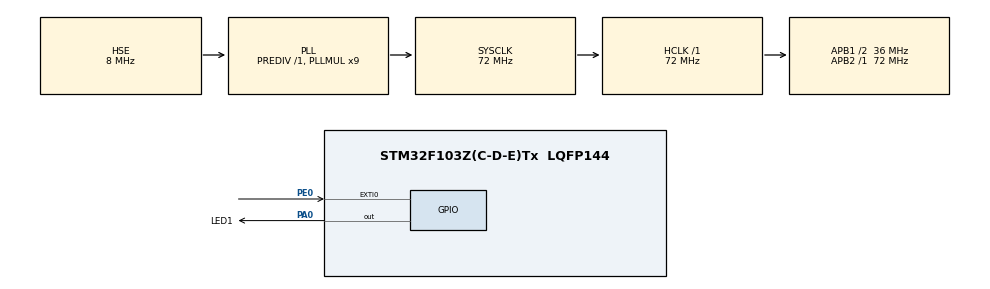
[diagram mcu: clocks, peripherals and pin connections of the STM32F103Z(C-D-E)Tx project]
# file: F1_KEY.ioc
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Mcu.Family=STM32F1
Mcu.Name=STM32F103Z(C-D-E)Tx
Mcu.Package=LQFP144
NVIC.EXTI0_IRQn=true\:0\:0\:false\:false\:true\:true\:true
NVIC.PriorityGroup=NVIC_PRIORITYGROUP_4
OSC_IN.Mode=HSE-External-Oscillator
OSC_IN.Signal=RCC_OSC_IN
OSC_OUT.Mode=HSE-External-Oscillator
OSC_OUT.Signal=RCC_OSC_OUT
PA0-WKUP.GPIO_Label=LED1
PA0-WKUP.PinState=GPIO_PIN_SET
PA0-WKUP.Signal=GPIO_Output
PA13.Mode=Serial_Wire
PA13.Signal=SYS_JTMS-SWDIO
PA14.Mode=Serial_Wire
PA14.Signal=SYS_JTCK-SWCLK
PE0.GPIO_ModeDefaultEXTI=GPIO_MODE_IT_FALLING
PE0.Signal=GPXTI0
ProjectManager.HeapSize=0x200
ProjectManager.StackSize=0x400
ProjectManager.TargetToolchain=MDK-ARM V5
RCC.AHBFreq_Value=72000000
RCC.APB1CLKDivider=RCC_HCLK_DIV2
RCC.APB1Freq_Value=36000000
RCC.APB1TimFreq_Value=72000000
RCC.APB2Freq_Value=72000000
RCC.APB2TimFreq_Value=72000000
RCC.HCLKFreq_Value=72000000
RCC.PLLMUL=RCC_PLL_MUL9
RCC.PLLSourceVirtual=RCC_PLLSOURCE_HSE
RCC.SYSCLKFreq_VALUE=72000000
RCC.SYSCLKSource=RCC_SYSCLKSOURCE_PLLCLK
RCC.USBFreq_Value=72000000
board=custom

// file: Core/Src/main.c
/* USER CODE BEGIN Header */
/**
  ******************************************************************************
  * @file           : main.c
  * @brief          : Main program body
  ******************************************************************************
  * @attention
  *
  * <h2><center>&copy; Copyright (c) 2019 STMicroelectronics.
  * All rights reserved.</center></h2>
  *
  * This software component is licensed by ST under BSD 3-Clause license,
  * the "License"; You may not use this file except in compliance with the
  * License. You may obtain a copy of the License at:
  *                        opensource.org/licenses/BSD-3-Clause
  *
  ******************************************************************************
  */
/* USER CODE END Header */

#include "main.h"
#include "gpio.h"

/* USER CODE BEGIN Includes */
#include "key.h"
#include "led.h"

/* USER CODE END Includes */

/* USER CODE BEGIN PV */
static volatile uint8_t flag = 0;

/* USER CODE END PV */

void SystemClock_Config(void);

int main(void)
{

  /* MCU Configuration--------------------------------------------------------*/

  /* Reset of all peripherals, Initializes the Flash interface and the Systick. */
  HAL_Init();

  /* Configure the system clock */
  SystemClock_Config();

  /* Initialize all configured peripherals */
  MX_GPIO_Init();
  /* USER CODE BEGIN 2 */
  uint32_t old_tick = HAL_GetTick();
  uint8_t status = 0;

  /* USER CODE END 2 */

  /* Infinite loop */
  /* USER CODE BEGIN WHILE */
  while (1)
  {
#if KEY_MODE == 0
	  if(KeyReadStatus() == KEY_PRESS)
	  {
		  HAL_Delay(10);
		  if(KeyReadStatus() == KEY_PRESS)
		  {
			  LED_Control(LED_ON);
			  while(KeyReadStatus() == KEY_PRESS);
			  LED_Control(LED_OFF);
		  }
	  }

#elif KEY_MODE == 1

	  uint32_t new_tick;
	  new_tick = HAL_GetTick();

	  if(new_tick > (old_tick + 10))
	  {
		  old_tick = new_tick;
          if(KeyReadStatus() == KEY_PRESS)
          {
                if(status == 0)
                    status = 1;
                else if(status == 1)
                {
                    status = 2;
                    LED_Control(LED_ON);
                }
          }
		  else
		  {
				if(status == 2)
				{
					status = 0;
					LED_Control(LED_OFF);
				}
		  }

	  }

#elif KEY_MODE == 2

	if(flag)
	{
		flag = 0;
		LED_Control(LED_ON);
	}

#elif KEY_MODE == 3

	HAL_PWR_EnterSTOPMode(PWR_LOWPOWERREGULATOR_ON, PWR_STOPENTRY_WFI);		//开启低功耗stop模式
	SystemClock_Config();		//重新配置时钟
	LED_Control(LED_ON);

#endif
    /* USER CODE END WHILE */

  }
}

void SystemClock_Config(void)
{
  RCC_OscInitTypeDef RCC_OscInitStruct = {0};
  RCC_ClkInitTypeDef RCC_ClkInitStruct = {0};

  /** Initializes the CPU, AHB and APB busses clocks
  */
  RCC_OscInitStruct.OscillatorType = RCC_OSCILLATORTYPE_HSE;
  RCC_OscInitStruct.HSEState = RCC_HSE_ON;
  RCC_OscInitStruct.HSEPredivValue = RCC_HSE_PREDIV_DIV1;
  RCC_OscInitStruct.HSIState = RCC_HSI_ON;
  RCC_OscInitStruct.PLL.PLLState = RCC_PLL_ON;
  RCC_OscInitStruct.PLL.PLLSource = RCC_PLLSOURCE_HSE;
  RCC_OscInitStruct.PLL.PLLMUL = RCC_PLL_MUL9;
  if (HAL_RCC_OscConfig(&RCC_OscInitStruct) != HAL_OK)
  {
    Error_Handler();
  }
  /** Initializes the CPU, AHB and APB busses clocks
  */
  RCC_ClkInitStruct.ClockType = RCC_CLOCKTYPE_HCLK|RCC_CLOCKTYPE_SYSCLK
                              |RCC_CLOCKTYPE_PCLK1|RCC_CLOCKTYPE_PCLK2;
  RCC_ClkInitStruct.SYSCLKSource = RCC_SYSCLKSOURCE_PLLCLK;
  RCC_ClkInitStruct.AHBCLKDivider = RCC_SYSCLK_DIV1;
  RCC_ClkInitStruct.APB1CLKDivider = RCC_HCLK_DIV2;
  RCC_ClkInitStruct.APB2CLKDivider = RCC_HCLK_DIV1;

  if (HAL_RCC_ClockConfig(&RCC_ClkInitStruct, FLASH_LATENCY_2) != HAL_OK)
  {
    Error_Handler();
  }
}

/* USER CODE BEGIN 4 */
void HAL_GPIO_EXTI_Callback(uint16_t GPIO_Pin)
{
	flag = 1;
}

/* USER CODE END 4 */

void Error_Handler(void)
{
}

/************************ (C) COPYRIGHT STMicroelectronics *****END OF FILE****/
